# S6E1B8xG register map
Vendor: Cypress; File version: 2.0
CPU: CM0PLUS r0p1, little endian, no MPU, no FPU, 2 interrupt priority bits
Registers are 8-bit, read-write, reset 0x0 unless marked. A register's access mark holds for its fields unless they carry their own. Offsets are from the block's base; [hi:lo] are bit positions; {n}, {i} and the like mark numbered series.

## MFSI2S0 — I2S0 Registers
Base 0x4003CA00
Same registers: MFSI2S1 0x4003CA80
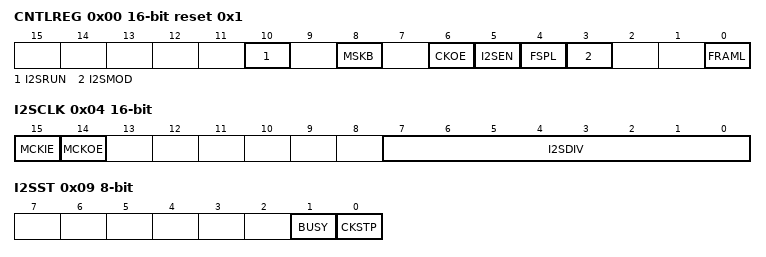
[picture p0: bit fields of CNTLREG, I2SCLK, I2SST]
0x00 CNTLREG 16-bit reset 0x1 — Control Register
  [10] I2SRUN — I2S clock generate enable bit
  [8] MSKB — Mask bit output bit
  [6] CKOE — I2SCK and I2SWS output enable bit
  [5] I2SEN — I2S mode enable bit
  [4] FSPL — I2SWS polarity set bit
  [3] I2SMOD — I2S mode select bit
  [0] FRAML — Frame length select bit
0x04 I2SCLK 16-bit — I2S Clock Register
  [15] MCKIE — Main clock input enable bit
  [14] MCKOE — Main clock output enable bit
  [7:0] I2SDIV — I2S clock division set bit
0x08 I2SRST wo — I2S Reset Register
  [7:0] I2SRST — I2S software reset bit
0x09 I2SST ro — I2S Status Register
  [1] BUSY — Bus busy indication for transmit bit
  [0] CKSTP — Clock stop indication bit

## DSTC — DSTC registers
Base 0x40061000
0x00 DESTP 32-bit — Descriptor top address Register
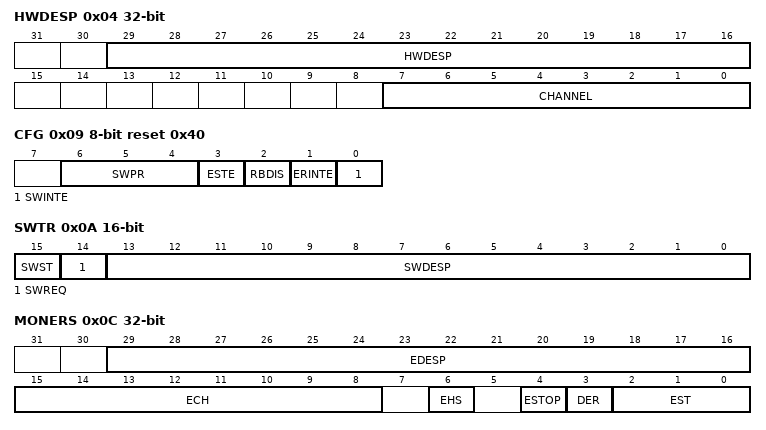
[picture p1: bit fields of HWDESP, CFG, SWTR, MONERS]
0x04 HWDESP 32-bit — Hardware DES pointer Register
  [29:16] HWDESP, [7:0] CHANNEL
0x08 CMD reset 0x1 — Command Register
0x09 CFG reset 0x40 — Configuration Register
  [6:4] SWPR — Software transfer priority
  [3] ESTE — Error stop enable
  [2] RBDIS — Read skip buffer disable
  [1] ERINTE — Error interrupt enable
  [0] SWINTE — Software interrupt enable
0x0A SWTR 16-bit — Software trigger Register
  [15] SWST ro — Software status
  [14] SWREQ ro — Software request
  [13:0] SWDESP — Software DES pointer
0x0C MONERS 32-bit — Transfer Error Status Monitor Register
  [29:16] EDESP ro — Error DES pointer
  [15:8] ECH ro — Error hardware channel
  [6] EHS ro — Error hardware software
  [4] ESTOP ro — Error stop
  [3] DER ro — Double error
  [2:0] EST ro — Error status
{0x10+4i} DREQENB{i} 32-bit (i=0..7) — DMA request enable Register {i}
{0x30+4i} HWINT{i} 32-bit (i=0..7) — Hardware transfer interrupt Register {i}
{0x50+4i} HWINTCLR{i} 32-bit (i=0..7) — Hardware transfer interrupt clear Register {i}
{0x70+4i} DQMSK{i} 32-bit (i=0..7) — DMA request mask Register {i}
{0x90+4i} DQMSKCLR{i} 32-bit (i=0..7) — DMA request mask clear Register {i}

## MTB_DWT — Micro Trace Buffer Data Watchpoint and Trace Registers
Base 0xF0001000
0x00 CMP_ADDR_START 32-bit — MTB_DWT Address Compare Start trace Register
  [31:0] ADCMP_STA — MTB_DWT address comparison start trace bits
0x04 CMP_DATA_START 32-bit — MTB_DWT Data Compare Start trace Register
  [31:0] DTCMP_STA — MTB_DWT data comparison start trace bits
0x08 CMP_MASK_START 32-bit — MTB_DWT Mask Data Compare Start Trace Register
  [31:0] MSK_STA — MTB_DWT data compare start trace register mask bits
0x10 CMP_ADDR_STOP 32-bit — MTB_DWT Address Compare Stop trace Register
  [31:0] ADCMP_STO — MTB_DWT address comparison stop trace bits
0x14 CMP_DATA_STOP 32-bit — MTB_DWT Data Compare Stop trace Register
  [31:0] DTCMP_STO — MTB_DWT data comparison stop trace bits
0x18 CMP_MASK_STOP 32-bit — MTB_DWT Mask Data Compare Stop Trace Register
  [31:0] MSK_STO — MTB_DWT data compare stop trace register mask bits
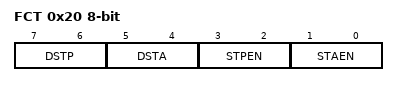
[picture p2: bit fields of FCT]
0x20 FCT — MTB_DWT Function Register
  [7:6] DSTP — Data size stop bits
  [5:4] DSTA — Data size start bits
  [3:2] STPEN — Enable MTB_DWT stop MTB function bits
  [1:0] STAEN — Enable MTB_DWT start MTB function bits
{0xFC0+4i} PID{i} 32-bit ro (i=4..7) — Peripheral ID{i} Register
  [31:0] PERID — Peripheral ID bits
0xFE0 PID0 32-bit ro reset 0x16 — Peripheral ID0 Register
  [31:0] PERID — Peripheral ID bits
0xFE4 PID1 32-bit ro reset 0x48 — Peripheral ID1 Register
  [31:0] PERID — Peripheral ID bits
0xFE8 PID2 32-bit ro reset 0x8 — Peripheral ID2 Register
  [31:0] PERID — Peripheral ID bits
0xFEC PID3 32-bit ro — Peripheral ID3 Register
  [31:0] PERID — Peripheral ID bits
0xFF0 CID0 32-bit ro reset 0xD — Component ID0 Register
  [31:0] CPNTID — Component ID bits
0xFF4 CID1 32-bit ro reset 0x90 — Component ID1 Register
  [31:0] CPNTID — Component ID bits
0xFF8 CID2 32-bit ro reset 0x5 — Component ID2 Register
  [31:0] CPNTID — Component ID bits
0xFFC CID3 32-bit ro reset 0xB1 — Component ID3 Register
  [31:0] CPNTID — Component ID bits

## VIR — Vector Indicate Registers
Base 0xF8000100
{0x0+4i} VIR{i:02} 32-bit ro (i=0..31) — Vector Indicate Register {i:02}
